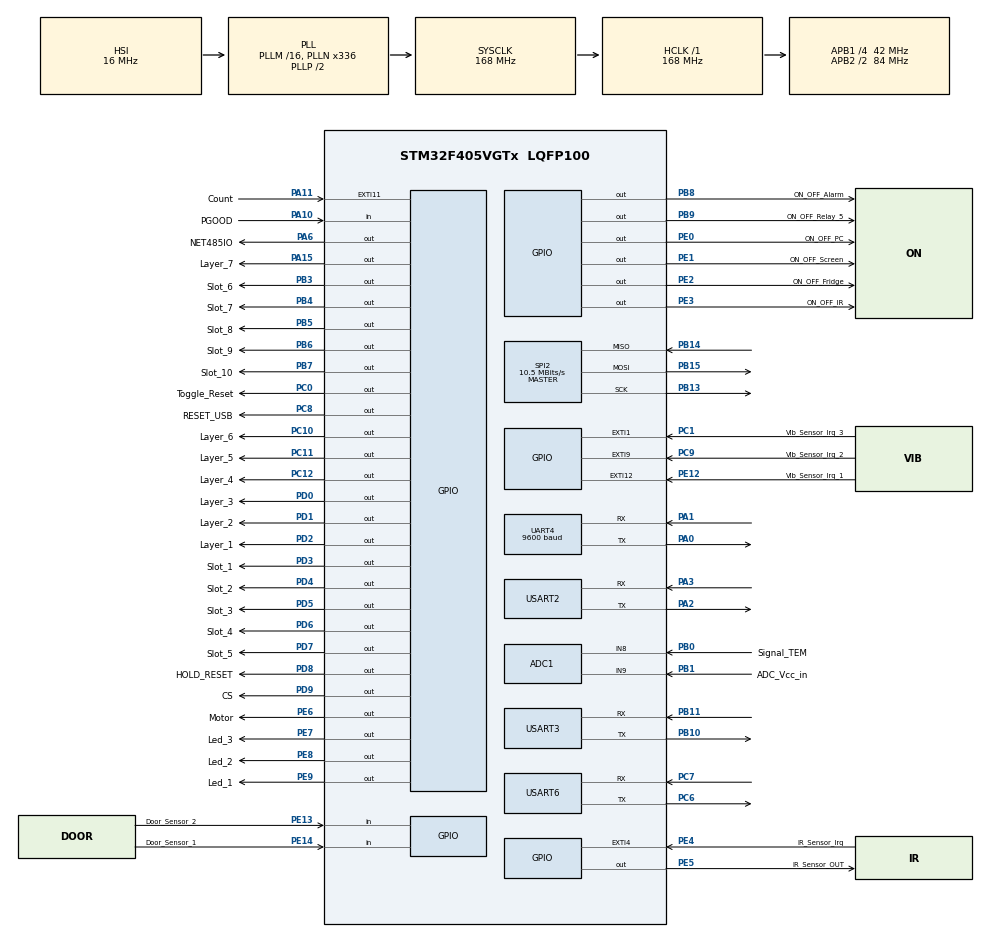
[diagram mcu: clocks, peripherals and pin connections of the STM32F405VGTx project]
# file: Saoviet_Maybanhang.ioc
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ADC1.Channel-0\#ChannelRegularConversion=ADC_CHANNEL_8
ADC1.Channel-1\#ChannelRegularConversion=ADC_CHANNEL_9
ADC1.Channel-3\#ChannelRegularConversion=ADC_CHANNEL_VREFINT
ADC1.ContinuousConvMode=DISABLE
ADC1.DMAContinuousRequests=DISABLE
ADC1.InjNumberOfConversion=0
ADC1.NbrOfConversion=3
ADC1.NbrOfConversionFlag=1
ADC1.Rank-0\#ChannelRegularConversion=1
ADC1.Rank-1\#ChannelRegularConversion=2
ADC1.Rank-3\#ChannelRegularConversion=3
ADC1.SamplingTime-0\#ChannelRegularConversion=ADC_SAMPLETIME_480CYCLES
ADC1.SamplingTime-1\#ChannelRegularConversion=ADC_SAMPLETIME_480CYCLES
ADC1.SamplingTime-3\#ChannelRegularConversion=ADC_SAMPLETIME_480CYCLES
ADC1.master=1
Dma.ADC1.0.Direction=DMA_PERIPH_TO_MEMORY
Dma.ADC1.0.FIFOMode=DMA_FIFOMODE_DISABLE
Dma.ADC1.0.Instance=DMA2_Stream0
Dma.ADC1.0.MemDataAlignment=DMA_MDATAALIGN_WORD
Dma.ADC1.0.MemInc=DMA_MINC_ENABLE
Dma.ADC1.0.Mode=DMA_NORMAL
Dma.ADC1.0.PeriphDataAlignment=DMA_PDATAALIGN_WORD
Dma.ADC1.0.PeriphInc=DMA_PINC_DISABLE
Dma.ADC1.0.Priority=DMA_PRIORITY_LOW
Dma.Request0=ADC1
Mcu.Family=STM32F4
Mcu.Name=STM32F405VGTx
Mcu.Package=LQFP100
NVIC.DMA2_Stream0_IRQn=true\:0\:0\:false\:false\:true\:false\:true\:true
NVIC.EXTI15_10_IRQn=true\:0\:0\:false\:false\:true\:true\:true\:true
NVIC.EXTI1_IRQn=true\:0\:0\:false\:false\:true\:true\:true\:true
NVIC.EXTI4_IRQn=true\:0\:0\:false\:false\:true\:true\:true\:true
NVIC.EXTI9_5_IRQn=true\:0\:0\:false\:false\:true\:true\:true\:true
NVIC.PriorityGroup=NVIC_PRIORITYGROUP_4
NVIC.UART4_IRQn=true\:0\:0\:false\:false\:true\:true\:true\:true
NVIC.USART2_IRQn=true\:0\:0\:false\:false\:true\:true\:true\:true
NVIC.USART3_IRQn=true\:0\:0\:false\:false\:true\:true\:true\:true
NVIC.USART6_IRQn=true\:1\:0\:true\:false\:true\:true\:true\:true
PA0-WKUP.Mode=Asynchronous
PA0-WKUP.Signal=UART4_TX
PA1.Mode=Asynchronous
PA1.Signal=UART4_RX
PA10.GPIO_Label=PGOOD
PA10.GPIO_PuPd=GPIO_PULLDOWN
PA10.Signal=GPIO_Input
PA11.GPIO_Label=Count
PA11.GPIO_ModeDefaultEXTI=GPIO_MODE_IT_FALLING
PA11.GPIO_PuPd=GPIO_PULLDOWN
PA11.Signal=GPXTI11
PA13.Mode=Serial_Wire
PA13.Signal=SYS_JTMS-SWDIO
PA14.Mode=Serial_Wire
PA14.Signal=SYS_JTCK-SWCLK
PA15.GPIO_Label=Layer_7
PA15.GPIO_PuPd=GPIO_PULLDOWN
PA15.Signal=GPIO_Output
PA2.Mode=Asynchronous
PA2.Signal=USART2_TX
PA3.Mode=Asynchronous
PA3.Signal=USART2_RX
PA6.GPIO_Label=NET485IO
PA6.GPIO_PuPd=GPIO_PULLDOWN
PA6.Signal=GPIO_Output
PB0.GPIO_Label=Signal_TEM
PB0.Signal=ADCx_IN8
PB1.GPIO_Label=ADC_Vcc_in
PB1.Signal=ADCx_IN9
PB10.Mode=Asynchronous
PB10.Signal=USART3_TX
PB11.Mode=Asynchronous
PB11.Signal=USART3_RX
PB13.Mode=Full_Duplex_Master
PB13.Signal=SPI2_SCK
PB14.Mode=Full_Duplex_Master
PB14.Signal=SPI2_MISO
PB15.Mode=Full_Duplex_Master
PB15.Signal=SPI2_MOSI
PB3.GPIO_Label=Slot_6
PB3.GPIO_PuPd=GPIO_PULLDOWN
PB3.Signal=GPIO_Output
PB4.GPIO_Label=Slot_7
PB4.GPIO_PuPd=GPIO_PULLDOWN
PB4.Signal=GPIO_Output
PB5.GPIO_Label=Slot_8
PB5.GPIO_PuPd=GPIO_PULLDOWN
PB5.Signal=GPIO_Output
PB6.GPIO_Label=Slot_9
PB6.GPIO_PuPd=GPIO_PULLDOWN
PB6.Signal=GPIO_Output
PB7.GPIO_Label=Slot_10
PB7.GPIO_PuPd=GPIO_PULLDOWN
PB7.Signal=GPIO_Output
PB8.GPIO_Label=ON_OFF_Alarm
PB8.GPIO_PuPd=GPIO_PULLDOWN
PB8.Signal=GPIO_Output
PB9.GPIO_Label=ON_OFF_Relay_5
PB9.GPIO_PuPd=GPIO_PULLDOWN
PB9.Signal=GPIO_Output
PC0.GPIO_Label=Toggle_Reset
PC0.GPIO_PuPd=GPIO_PULLDOWN
PC0.Signal=GPIO_Output
PC1.GPIO_Label=Vib_Sensor_Irq_3
PC1.GPIO_ModeDefaultEXTI=GPIO_MODE_IT_RISING
PC1.GPIO_PuPd=GPIO_PULLDOWN
PC1.Signal=GPXTI1
PC10.GPIO_Label=Layer_6
PC10.GPIO_PuPd=GPIO_PULLDOWN
PC10.Signal=GPIO_Output
PC11.GPIO_Label=Layer_5
PC11.GPIO_PuPd=GPIO_PULLDOWN
PC11.Signal=GPIO_Output
PC12.GPIO_Label=Layer_4
PC12.GPIO_PuPd=GPIO_PULLDOWN
PC12.Signal=GPIO_Output
PC6.Mode=Asynchronous
PC6.Signal=USART6_TX
PC7.Mode=Asynchronous
PC7.Signal=USART6_RX
PC8.GPIO_Label=RESET_USB
PC8.GPIO_PuPd=GPIO_PULLDOWN
PC8.Signal=GPIO_Output
PC9.GPIO_Label=Vib_Sensor_Irq_2
PC9.GPIO_PuPd=GPIO_PULLDOWN
PC9.Signal=GPXTI9
PD0.GPIO_Label=Layer_3
PD0.GPIO_PuPd=GPIO_PULLDOWN
PD0.Signal=GPIO_Output
PD1.GPIO_Label=Layer_2
PD1.GPIO_PuPd=GPIO_PULLDOWN
PD1.Signal=GPIO_Output
PD2.GPIO_Label=Layer_1
PD2.GPIO_PuPd=GPIO_PULLDOWN
PD2.Signal=GPIO_Output
PD3.GPIO_Label=Slot_1
PD3.GPIO_PuPd=GPIO_PULLDOWN
PD3.Signal=GPIO_Output
PD4.GPIO_Label=Slot_2
PD4.GPIO_PuPd=GPIO_PULLDOWN
PD4.Signal=GPIO_Output
PD5.GPIO_Label=Slot_3
PD5.GPIO_PuPd=GPIO_PULLDOWN
PD5.Signal=GPIO_Output
PD6.GPIO_Label=Slot_4
PD6.GPIO_PuPd=GPIO_PULLDOWN
PD6.Signal=GPIO_Output
PD7.GPIO_Label=Slot_5
PD7.GPIO_PuPd=GPIO_PULLDOWN
PD7.Signal=GPIO_Output
PD8.GPIO_Label=HOLD_RESET
PD8.GPIO_PuPd=GPIO_PULLUP
PD8.PinState=GPIO_PIN_SET
PD8.Signal=GPIO_Output
PD9.GPIO_Label=CS
PD9.GPIO_PuPd=GPIO_PULLDOWN
PD9.Signal=GPIO_Output
PE0.GPIO_Label=ON_OFF_PC
PE0.GPIO_PuPd=GPIO_PULLDOWN
PE0.PinState=GPIO_PIN_RESET
PE0.Signal=GPIO_Output
PE1.GPIO_Label=ON_OFF_Screen
PE1.GPIO_PuPd=GPIO_PULLDOWN
PE1.Signal=GPIO_Output
PE12.GPIO_Label=Vib_Sensor_Irq_1
PE12.GPIO_PuPd=GPIO_PULLDOWN
PE12.Signal=GPXTI12
PE13.GPIO_Label=Door_Sensor_2
PE13.GPIO_PuPd=GPIO_PULLDOWN
PE13.Signal=GPIO_Input
PE14.GPIO_Label=Door_Sensor_1
PE14.GPIO_PuPd=GPIO_PULLDOWN
PE14.Signal=GPIO_Input
PE2.GPIO_Label=ON_OFF_Fridge
PE2.GPIO_PuPd=GPIO_PULLDOWN
PE2.Signal=GPIO_Output
PE3.GPIO_Label=ON_OFF_IR
PE3.GPIO_PuPd=GPIO_PULLDOWN
PE3.Signal=GPIO_Output
PE4.GPIO_Label=IR_Sensor_Irq
PE4.GPIO_ModeDefaultEXTI=GPIO_MODE_IT_RISING
PE4.GPIO_PuPd=GPIO_PULLDOWN
PE4.Signal=GPXTI4
PE5.GPIO_Label=IR_Sensor_OUT
PE5.GPIO_PuPd=GPIO_PULLDOWN
PE5.Signal=GPIO_Output
PE6.GPIO_Label=Motor
PE6.GPIO_PuPd=GPIO_PULLDOWN
PE6.Signal=GPIO_Output
PE7.GPIO_Label=Led_3
PE7.GPIO_PuPd=GPIO_PULLDOWN
PE7.Signal=GPIO_Output
PE8.GPIO_Label=Led_2
PE8.GPIO_PuPd=GPIO_PULLDOWN
PE8.Signal=GPIO_Output
PE9.GPIO_Label=Led_1
PE9.GPIO_PuPd=GPIO_PULLDOWN
PE9.Signal=GPIO_Output
ProjectManager.HeapSize=0x200
ProjectManager.StackSize=0x400
ProjectManager.TargetToolchain=EWARM V8.32
RCC.48MHZClocksFreq_Value=84000000
RCC.AHBFreq_Value=168000000
RCC.APB1CLKDivider=RCC_HCLK_DIV4
RCC.APB1Freq_Value=42000000
RCC.APB1TimFreq_Value=84000000
RCC.APB2CLKDivider=RCC_HCLK_DIV2
RCC.APB2Freq_Value=84000000
RCC.APB2TimFreq_Value=168000000
RCC.CortexFreq_Value=168000000
RCC.HCLKFreq_Value=168000000
RCC.HSE_VALUE=25000000
RCC.HSI_VALUE=16000000
RCC.LSE_VALUE=32768
RCC.PLLN=336
RCC.SYSCLKFreq_VALUE=168000000
RCC.SYSCLKSource=RCC_SYSCLKSOURCE_PLLCLK
RCC.VCOOutputFreq_Value=336000000
SH.ADCx_IN8.0=ADC1_IN8,IN8
SH.ADCx_IN9.0=ADC1_IN9,IN9
SPI2.BaudRatePrescaler=SPI_BAUDRATEPRESCALER_4
SPI2.CalculateBaudRate=10.5 MBits/s
SPI2.Direction=SPI_DIRECTION_2LINES
SPI2.Mode=SPI_MODE_MASTER
SPI2.VirtualType=VM_MASTER
UART4.BaudRate=9600
UART4.VirtualMode=Asynchronous
USART2.VirtualMode=VM_ASYNC
USART3.VirtualMode=VM_ASYNC
USART6.VirtualMode=VM_ASYNC
VP_ADC1_Vref_Input.Mode=IN-Vrefint
board=custom

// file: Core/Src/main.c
/* USER CODE BEGIN Header */
/**
  ******************************************************************************
  * @file           : main.c
  * @brief          : Main program body
  ******************************************************************************
  * @attention
  *
  * Copyright (c) 2023 STMicroelectronics.
  * All rights reserved.
  *
  * This software is licensed under terms that can be found in the LICENSE file
  * in the root directory of this software component.
  * If no LICENSE file comes with this software, it is provided AS-IS.
  *
  ******************************************************************************
  */
/* USER CODE END Header */
#include "main.h"
#include "adc.h"
#include "dma.h"
#include "spi.h"
#include "usart.h"
#include "gpio.h"

/* USER CODE BEGIN Includes */
#include "user_app_comm.h"
#include "onchipflash.h"
#include "user_external_flash.h"
/* USER CODE END Includes */

void SystemClock_Config(void);

int main(void)
{

  /* MCU Configuration--------------------------------------------------------*/

  /* Reset of all peripherals, Initializes the Flash interface and the Systick. */
  HAL_Init();

  /* Configure the system clock */
  SystemClock_Config();

  /* Initialize all configured peripherals */
  MX_GPIO_Init();
  MX_DMA_Init();
  MX_ADC1_Init();
  MX_USART3_UART_Init();
  MX_USART6_UART_Init();
  MX_UART4_Init();
  MX_USART2_UART_Init();
  MX_SPI2_Init();
  /* USER CODE BEGIN 2 */

  Main_Task();

  /* USER CODE END 2 */

  /* Infinite loop */
  while (1)
  {

  }
}

void SystemClock_Config(void)
{
  RCC_OscInitTypeDef RCC_OscInitStruct = {0};
  RCC_ClkInitTypeDef RCC_ClkInitStruct = {0};

  /** Configure the main internal regulator output voltage
  */
  __HAL_RCC_PWR_CLK_ENABLE();
  __HAL_PWR_VOLTAGESCALING_CONFIG(PWR_REGULATOR_VOLTAGE_SCALE1);

  /** Initializes the RCC Oscillators according to the specified parameters
  * in the RCC_OscInitTypeDef structure.
  */
  RCC_OscInitStruct.OscillatorType = RCC_OSCILLATORTYPE_HSI;
  RCC_OscInitStruct.HSIState = RCC_HSI_ON;
  RCC_OscInitStruct.HSICalibrationValue = RCC_HSICALIBRATION_DEFAULT;
  RCC_OscInitStruct.PLL.PLLState = RCC_PLL_ON;
  RCC_OscInitStruct.PLL.PLLSource = RCC_PLLSOURCE_HSI;
  RCC_OscInitStruct.PLL.PLLM = 16;
  RCC_OscInitStruct.PLL.PLLN = 336;
  RCC_OscInitStruct.PLL.PLLP = RCC_PLLP_DIV2;
  RCC_OscInitStruct.PLL.PLLQ = 4;
  if (HAL_RCC_OscConfig(&RCC_OscInitStruct) != HAL_OK)
  {
    Error_Handler();
  }

  /** Initializes the CPU, AHB and APB buses clocks
  */
  RCC_ClkInitStruct.ClockType = RCC_CLOCKTYPE_HCLK|RCC_CLOCKTYPE_SYSCLK
                              |RCC_CLOCKTYPE_PCLK1|RCC_CLOCKTYPE_PCLK2;
  RCC_ClkInitStruct.SYSCLKSource = RCC_SYSCLKSOURCE_PLLCLK;
  RCC_ClkInitStruct.AHBCLKDivider = RCC_SYSCLK_DIV1;
  RCC_ClkInitStruct.APB1CLKDivider = RCC_HCLK_DIV4;
  RCC_ClkInitStruct.APB2CLKDivider = RCC_HCLK_DIV2;

  if (HAL_RCC_ClockConfig(&RCC_ClkInitStruct, FLASH_LATENCY_5) != HAL_OK)
  {
    Error_Handler();
  }
}

void Error_Handler(void)
{
  __disable_irq();
  while (1)
  {
  }
}
